# ADSP-SC83xW_HPC register map
Vendor: Analog Devices; Series: ADSP-SC83xW_HPC; File version: 3.0.3.517
CPU: 
Registers are 32-bit, read-write, reset 0x0 unless marked. A register's access mark holds for its fields unless they carry their own. Offsets are from the block's base; [hi:lo] are bit positions; {n}, {i} and the like mark numbered series.

## LP0 — Link Port
Base 0x30FFE000
Same registers: LP1 0x30FFE100
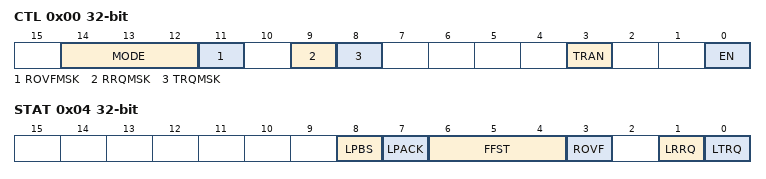
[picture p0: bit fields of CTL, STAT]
0x00 CTL — Control Register
  [14:12] MODE — Mode Select
    0=8BIT_SDR; 1=4BIT_SDR; 2=2BIT_SDR; 4=8BIT_DDR; 5=4BIT_DDR; 6=2BIT_DDR
  [11] ROVFMSK — Receive FIFO Overflow Interrupt Mask
    0=RX_OVF_DIS (Mask); 1=RX_OVF_EN (Unmask)
  [9] RRQMSK — Receive Request Interrupt Mask
    0=RRQ_DIS (Mask); 1=RRQ_EN (Unmask)
  [8] TRQMSK — Transmit Request Interrupt Mask
    0=TRQ_DIS (Mask); 1=TRQ_EN (Unmask)
  [3] TRAN — Transfer Direction
    0=RX (Receive); 1=TX (Transmit)
  [0] EN — Enable
    0=DIS (Disable); 1=EN (Enable linkport)
0x04 STAT — Status Register
  [8] LPBS ro — Bus Status
    0=IDLE (Link port bus is idle); 1=BUSY (Link port bus is busy)
  [7] LPACK ro — Buffer Pack Status
    0=PACK_DONE (Packing Complete); 1=PACK_PROG (Packing Incomplete)
  [6:4] FFST ro — FIFO Status
    0=RX0_TX0 (TX - Empty; RX - Empty); 1=RX1_TXR (TX - Reserved ; RX - Has 1 data word); 2=RX2_TXR (TX - Reserved; RX - Has 2 data words); 3=RX3_TXR (TX - Reserved; RX - Has 3 data words); 4=RX4_TX1 (TX - One Word; RX -Has 4 data words); 6=RXR2_TXR2 (TX - FIFO Full; RX - Reserved)
  [3] ROVF range 0x00000000..0x00000001 — Receive FIFO Overflow Interrupt
  [1] LRRQ range 0x00000000..0x00000001 — Receive Request
  [0] LTRQ range 0x00000000..0x00000001 — Transmit Request
0x08 DIV — Clock Divider Value Register
  [7:0] VALUE range 0x00000000..0x000000FF — Divisor Value
0x10 TX — Transmit Buffer Register
  [31:0] DATA range 0x00000000..0xFFFFFFFF — Transmit Data Buffer
0x14 RX — Receive Buffer Register
  [31:0] DATA range 0x00000000..0xFFFFFFFF — Receive Buffer
0x18 TXIN_SHDW — Shadow Input Transmit Buffer Register
  [31:0] DATA ro — Transmit Data Buffer Shadow Input Stage
0x1C TXOUT_SHDW — Shadow Output Transmit Buffer Register
  [31:0] DATA ro — Transmit Data Output Shadow Register

## PORTA — The General-Purpose Input/Output Port
Base 0x31004000
Same registers: PORTB 0x31004080, PORTC 0x31004100, PORTD 0x31004180, PORTE 0x31004200, PORTF 0x31004280
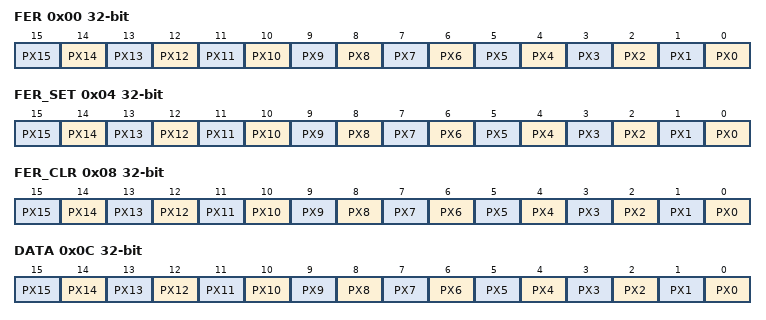
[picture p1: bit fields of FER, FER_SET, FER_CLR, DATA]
0x00 FER — Port x Function Enable Register
  [n] PX{n} (n=0..15) — Port x Bit {n} Mode
0x04 FER_SET — Port x Function Enable Set Register
  [n] PX{n} (n=0..15) — Port x Bit {n} Mode Set
0x08 FER_CLR — Port x Function Enable Clear Register
  [n] PX{n} (n=0..15) — Port x Bit {n} Mode Clear
0x0C DATA — Port x GPIO Data Register
  [n] PX{n} (n=0..15) — Port x Bit {n} Data
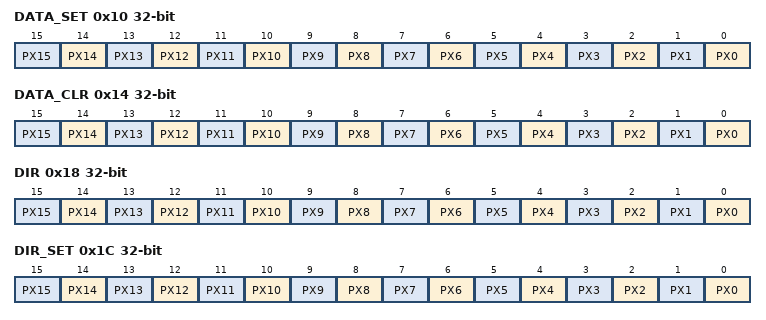
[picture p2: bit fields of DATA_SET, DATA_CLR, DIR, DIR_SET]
0x10 DATA_SET — Port x GPIO Data Set Register
  [n] PX{n} (n=0..15) — Port x Bit {n} Data Set
0x14 DATA_CLR — Port x GPIO Data Clear Register
  [n] PX{n} (n=0..15) — Port x Bit {n} Data Clear
0x18 DIR — Port x GPIO Direction Register
  [n] PX{n} (n=0..15) — Port x Bit {n} Direction
0x1C DIR_SET — Port x GPIO Direction Set Register
  [n] PX{n} (n=0..15) — Port x Bit {n} Direction Set
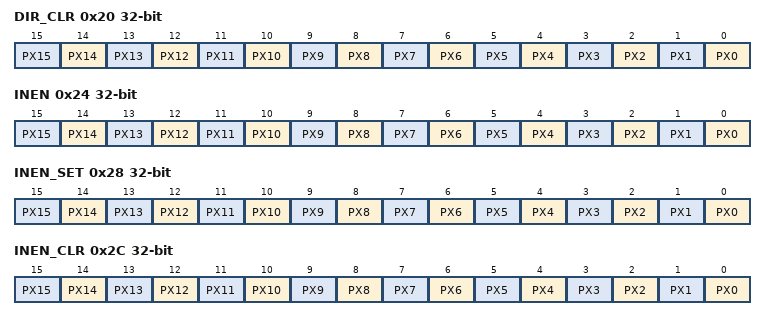
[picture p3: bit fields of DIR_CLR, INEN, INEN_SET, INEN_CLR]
0x20 DIR_CLR — Port x GPIO Direction Clear Register
  [n] PX{n} (n=0..15) — Port x Bit {n} Direction Clear
0x24 INEN — Port x GPIO Input Enable Register
  [n] PX{n} (n=0..15) — Port x Bit {n} Input Enable
0x28 INEN_SET — Port x GPIO Input Enable Set Register
  [n] PX{n} (n=0..15) — Port x Bit {n} Input Enable Set
0x2C INEN_CLR — Port x GPIO Input Enable Clear Register
  [n] PX{n} (n=0..15) — Port x Bit {n} Input Enable Clear
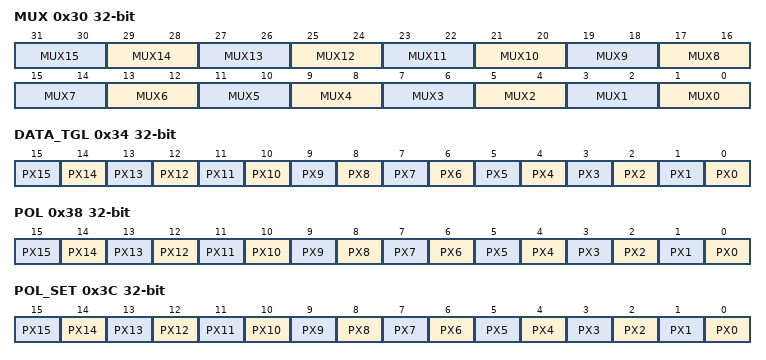
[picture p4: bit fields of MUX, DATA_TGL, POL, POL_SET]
0x30 MUX — Port x Multiplexer Control Register
  [2n+1:2n] MUX{n} range 0x00000000..0x00000003 (n=0..15) — Mux for Port x Bit {n}
0x34 DATA_TGL — Port x GPIO Output Toggle Register
  [n] PX{n} (n=0..15) — Port x Bit {n} Toggle
0x38 POL — Port x GPIO Polarity Invert Register
  [n] PX{n} (n=0..15) — Port x Bit {n} Polarity Invert
0x3C POL_SET — Port x GPIO Polarity Invert Set Register
  [n] PX{n} (n=0..15) — Port x Bit {n} Polarity Invert Set
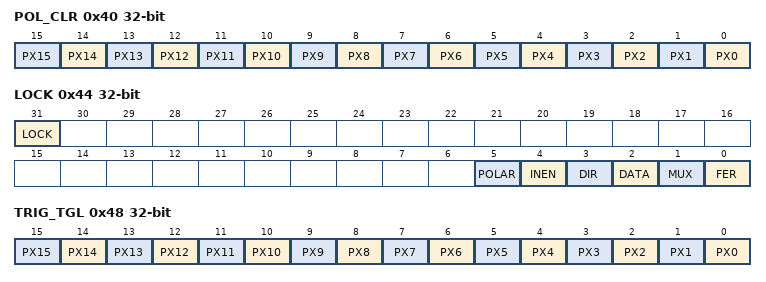
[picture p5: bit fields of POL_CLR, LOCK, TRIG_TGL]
0x40 POL_CLR — Port x GPIO Polarity Invert Clear Register
  [n] PX{n} (n=0..15) — Port x Bit {n} Polarity Invert Clear
0x44 LOCK — Port x GPIO Lock Register
  [31] LOCK
  [5] POLAR — Polarity Lock
  [4] INEN — Input Enable Lock
  [3] DIR — Direction Lock
  [2] DATA — Data, TGL Lock
  [1] MUX — Function Multiplexer Lock
  [0] FER — Function Enable Lock
0x48 TRIG_TGL — Port x GPIO Trigger Toggle Register
  [n] PX{n} range 0x00000000..0x00000001 (n=0..15) — PX{n} Data Toggle on Trigger
